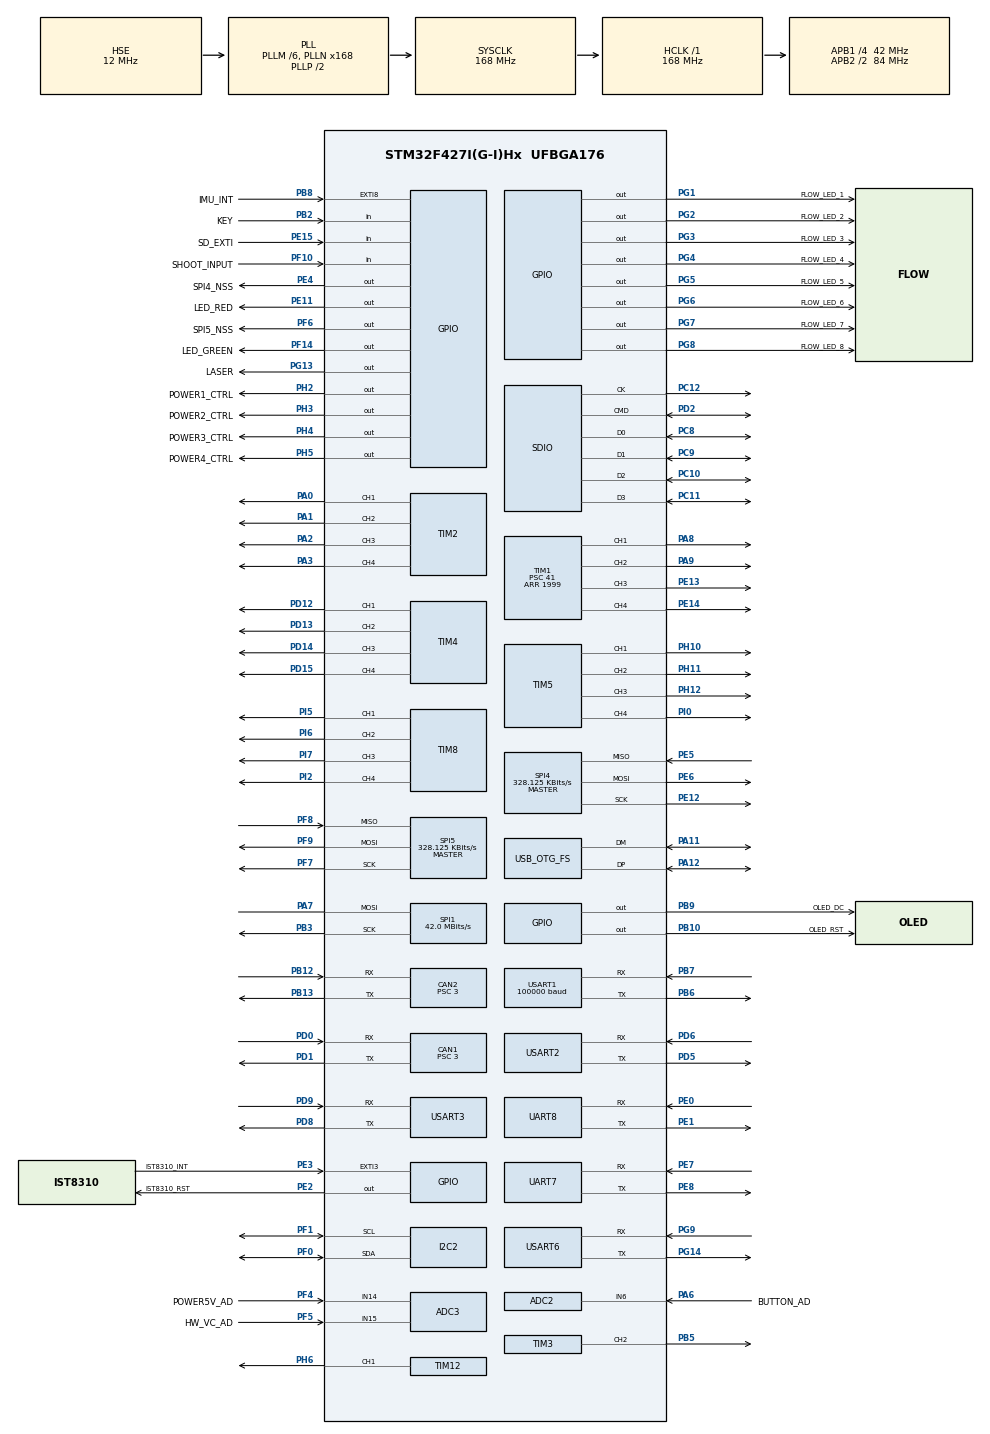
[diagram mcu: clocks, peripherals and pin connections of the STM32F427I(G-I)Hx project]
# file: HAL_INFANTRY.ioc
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ADC1.Channel-1\#ChannelRegularConversion=ADC_CHANNEL_TEMPSENSOR
ADC1.NbrOfConversionFlag=1
ADC1.Rank-1\#ChannelRegularConversion=1
ADC1.SamplingTime-1\#ChannelRegularConversion=ADC_SAMPLETIME_3CYCLES
ADC1.master=1
ADC2.Channel-0\#ChannelRegularConversion=ADC_CHANNEL_6
ADC2.NbrOfConversionFlag=1
ADC2.Rank-0\#ChannelRegularConversion=1
ADC2.SamplingTime-0\#ChannelRegularConversion=ADC_SAMPLETIME_3CYCLES
ADC3.Channel-0\#ChannelRegularConversion=ADC_CHANNEL_14
ADC3.NbrOfConversionFlag=1
ADC3.Rank-0\#ChannelRegularConversion=1
ADC3.SamplingTime-0\#ChannelRegularConversion=ADC_SAMPLETIME_3CYCLES
CAN1.BS1=CAN_BS1_10TQ
CAN1.BS2=CAN_BS2_3TQ
CAN1.CalculateTimeQuantum=71.42857142857143
CAN1.Prescaler=3
CAN2.BS1=CAN_BS1_10TQ
CAN2.BS2=CAN_BS2_3TQ
CAN2.CalculateTimeQuantum=71.42857142857143
CAN2.Prescaler=3
Dma.Request0=USART1_RX
Dma.Request1=USART6_RX
Dma.Request2=USART6_TX
Dma.Request3=SPI5_RX
Dma.Request4=SPI5_TX
Dma.Request5=USART2_RX
Dma.Request6=USART2_TX
Dma.SPI5_RX.3.Direction=DMA_PERIPH_TO_MEMORY
Dma.SPI5_RX.3.FIFOMode=DMA_FIFOMODE_DISABLE
Dma.SPI5_RX.3.Instance=DMA2_Stream5
Dma.SPI5_RX.3.MemDataAlignment=DMA_MDATAALIGN_BYTE
Dma.SPI5_RX.3.MemInc=DMA_MINC_ENABLE
Dma.SPI5_RX.3.Mode=DMA_NORMAL
Dma.SPI5_RX.3.PeriphDataAlignment=DMA_PDATAALIGN_BYTE
Dma.SPI5_RX.3.PeriphInc=DMA_PINC_DISABLE
Dma.SPI5_RX.3.Priority=DMA_PRIORITY_HIGH
Dma.SPI5_TX.4.Direction=DMA_MEMORY_TO_PERIPH
Dma.SPI5_TX.4.FIFOMode=DMA_FIFOMODE_DISABLE
Dma.SPI5_TX.4.Instance=DMA2_Stream4
Dma.SPI5_TX.4.MemDataAlignment=DMA_MDATAALIGN_BYTE
Dma.SPI5_TX.4.MemInc=DMA_MINC_ENABLE
Dma.SPI5_TX.4.Mode=DMA_NORMAL
Dma.SPI5_TX.4.PeriphDataAlignment=DMA_PDATAALIGN_BYTE
Dma.SPI5_TX.4.PeriphInc=DMA_PINC_DISABLE
Dma.SPI5_TX.4.Priority=DMA_PRIORITY_MEDIUM
Dma.USART1_RX.0.Direction=DMA_PERIPH_TO_MEMORY
Dma.USART1_RX.0.FIFOMode=DMA_FIFOMODE_DISABLE
Dma.USART1_RX.0.Instance=DMA2_Stream2
Dma.USART1_RX.0.MemDataAlignment=DMA_MDATAALIGN_BYTE
Dma.USART1_RX.0.MemInc=DMA_MINC_ENABLE
Dma.USART1_RX.0.Mode=DMA_CIRCULAR
Dma.USART1_RX.0.PeriphDataAlignment=DMA_PDATAALIGN_BYTE
Dma.USART1_RX.0.PeriphInc=DMA_PINC_DISABLE
Dma.USART1_RX.0.Priority=DMA_PRIORITY_VERY_HIGH
Dma.USART2_RX.5.Direction=DMA_PERIPH_TO_MEMORY
Dma.USART2_RX.5.FIFOMode=DMA_FIFOMODE_DISABLE
Dma.USART2_RX.5.Instance=DMA1_Stream5
Dma.USART2_RX.5.MemDataAlignment=DMA_MDATAALIGN_BYTE
Dma.USART2_RX.5.MemInc=DMA_MINC_ENABLE
Dma.USART2_RX.5.Mode=DMA_CIRCULAR
Dma.USART2_RX.5.PeriphDataAlignment=DMA_PDATAALIGN_BYTE
Dma.USART2_RX.5.PeriphInc=DMA_PINC_DISABLE
Dma.USART2_RX.5.Priority=DMA_PRIORITY_LOW
Dma.USART2_TX.6.Direction=DMA_MEMORY_TO_PERIPH
Dma.USART2_TX.6.FIFOMode=DMA_FIFOMODE_DISABLE
Dma.USART2_TX.6.Instance=DMA1_Stream6
Dma.USART2_TX.6.MemDataAlignment=DMA_MDATAALIGN_BYTE
Dma.USART2_TX.6.MemInc=DMA_MINC_ENABLE
Dma.USART2_TX.6.Mode=DMA_NORMAL
Dma.USART2_TX.6.PeriphDataAlignment=DMA_PDATAALIGN_BYTE
Dma.USART2_TX.6.PeriphInc=DMA_PINC_DISABLE
Dma.USART2_TX.6.Priority=DMA_PRIORITY_LOW
Dma.USART6_RX.1.Direction=DMA_PERIPH_TO_MEMORY
Dma.USART6_RX.1.FIFOMode=DMA_FIFOMODE_DISABLE
Dma.USART6_RX.1.Instance=DMA2_Stream1
Dma.USART6_RX.1.MemDataAlignment=DMA_MDATAALIGN_BYTE
Dma.USART6_RX.1.MemInc=DMA_MINC_ENABLE
Dma.USART6_RX.1.Mode=DMA_NORMAL
Dma.USART6_RX.1.PeriphDataAlignment=DMA_PDATAALIGN_BYTE
Dma.USART6_RX.1.PeriphInc=DMA_PINC_DISABLE
Dma.USART6_RX.1.Priority=DMA_PRIORITY_LOW
Dma.USART6_TX.2.Direction=DMA_MEMORY_TO_PERIPH
Dma.USART6_TX.2.FIFOMode=DMA_FIFOMODE_DISABLE
Dma.USART6_TX.2.Instance=DMA2_Stream6
Dma.USART6_TX.2.MemDataAlignment=DMA_MDATAALIGN_BYTE
Dma.USART6_TX.2.MemInc=DMA_MINC_ENABLE
Dma.USART6_TX.2.Mode=DMA_NORMAL
Dma.USART6_TX.2.PeriphDataAlignment=DMA_PDATAALIGN_BYTE
Dma.USART6_TX.2.PeriphInc=DMA_PINC_DISABLE
Dma.USART6_TX.2.Priority=DMA_PRIORITY_LOW
FREERTOS.INCLUDE_pcTaskGetTaskName=1
FREERTOS.INCLUDE_uxTaskGetStackHighWaterMark=1
FREERTOS.INCLUDE_xTaskGetHandle=1
FREERTOS.Tasks01=led_trigger,-2,128,led_trigger_task,As weak,NULL,Dynamic,NULL,NULL
I2C2.I2C_Mode=I2C_Fast
Mcu.Family=STM32F4
Mcu.Name=STM32F427I(G-I)Hx
Mcu.Package=UFBGA176
NVIC.CAN1_RX0_IRQn=true\:5\:0\:false\:false\:true\:true\:true\:true
NVIC.CAN2_RX0_IRQn=true\:5\:0\:false\:false\:true\:true\:true\:true
NVIC.DMA1_Stream5_IRQn=true\:5\:0\:true\:false\:false\:true\:false\:false
NVIC.DMA1_Stream6_IRQn=true\:5\:0\:false\:false\:false\:true\:false\:false
NVIC.DMA2_Stream1_IRQn=true\:5\:0\:false\:false\:true\:true\:false\:true
NVIC.DMA2_Stream2_IRQn=true\:5\:0\:false\:false\:false\:true\:false\:false
NVIC.DMA2_Stream4_IRQn=true\:5\:0\:false\:false\:true\:true\:false\:true
NVIC.DMA2_Stream5_IRQn=true\:5\:0\:false\:false\:false\:true\:false\:false
NVIC.DMA2_Stream6_IRQn=true\:5\:0\:false\:false\:true\:true\:false\:true
NVIC.EXTI3_IRQn=true\:5\:0\:false\:false\:true\:true\:true\:true
NVIC.EXTI9_5_IRQn=true\:5\:0\:false\:false\:true\:true\:true\:true
NVIC.OTG_FS_IRQn=true\:5\:0\:false\:false\:true\:true\:true\:true
NVIC.PriorityGroup=NVIC_PRIORITYGROUP_4
NVIC.USART1_IRQn=true\:5\:0\:false\:false\:false\:true\:true\:false
NVIC.USART2_IRQn=true\:5\:0\:false\:false\:false\:true\:true\:false
PA0/WKUP.Signal=S_TIM2_CH1_ETR
PA1.Signal=S_TIM2_CH2
PA11.Mode=Device_Only
PA11.Signal=USB_OTG_FS_DM
PA12.Mode=Device_Only
PA12.Signal=USB_OTG_FS_DP
PA13.Mode=Serial_Wire
PA13.Signal=SYS_JTMS-SWDIO
PA14.Mode=Serial_Wire
PA14.Signal=SYS_JTCK-SWCLK
PA2.Signal=S_TIM2_CH3
PA3.Signal=S_TIM2_CH4
PA6.GPIO_Label=BUTTON_AD
PA6.Signal=ADCx_IN6
PA7.Mode=Simplex_Bidirectional_Master
PA7.Signal=SPI1_MOSI
PA8.Signal=S_TIM1_CH1
PA9.Signal=S_TIM1_CH2
PB10.GPIO_Label=OLED_RST
PB10.GPIO_PuPd=GPIO_PULLUP
PB10.GPIO_Speed=GPIO_SPEED_FREQ_LOW
PB10.PinState=GPIO_PIN_SET
PB10.Signal=GPIO_Output
PB12.Mode=Slave
PB12.Signal=CAN2_RX
PB13.Mode=Slave
PB13.Signal=CAN2_TX
PB2/BOOT1.GPIO_Label=KEY
PB2/BOOT1.Signal=GPIO_Input
PB3.Mode=Simplex_Bidirectional_Master
PB3.Signal=SPI1_SCK
PB5.Signal=S_TIM3_CH2
PB6.Mode=Asynchronous
PB6.Signal=USART1_TX
PB7.Mode=Asynchronous
PB7.Signal=USART1_RX
PB8.GPIO_Label=IMU_INT
PB8.GPIO_ModeDefaultEXTI=GPIO_MODE_IT_FALLING
PB8.GPIO_PuPd=GPIO_PULLUP
PB8.Signal=GPXTI8
PB9.GPIO_Label=OLED_DC
PB9.GPIO_PuPd=GPIO_PULLUP
PB9.GPIO_Speed=GPIO_SPEED_FREQ_VERY_HIGH
PB9.PinState=GPIO_PIN_SET
PB9.Signal=GPIO_Output
PC10.Mode=SD_4_bits_Wide_bus
PC10.Signal=SDIO_D2
PC11.Mode=SD_4_bits_Wide_bus
PC11.Signal=SDIO_D3
PC12.Mode=SD_4_bits_Wide_bus
PC12.Signal=SDIO_CK
PC8.Mode=SD_4_bits_Wide_bus
PC8.Signal=SDIO_D0
PC9.Mode=SD_4_bits_Wide_bus
PC9.Signal=SDIO_D1
PD0.Mode=Master
PD0.Signal=CAN1_RX
PD1.Mode=Master
PD1.Signal=CAN1_TX
PD12.Signal=S_TIM4_CH1
PD13.Signal=S_TIM4_CH2
PD14.Signal=S_TIM4_CH3
PD15.Signal=S_TIM4_CH4
PD2.Mode=SD_4_bits_Wide_bus
PD2.Signal=SDIO_CMD
PD5.Mode=Asynchronous
PD5.Signal=USART2_TX
PD6.Mode=Asynchronous
PD6.Signal=USART2_RX
PD8.Mode=Asynchronous
PD8.Signal=USART3_TX
PD9.Mode=Asynchronous
PD9.Signal=USART3_RX
PE0.Mode=Asynchronous
PE0.Signal=UART8_RX
PE1.Mode=Asynchronous
PE1.Signal=UART8_TX
PE11.GPIO_Label=LED_RED
PE11.GPIO_ModeDefaultOutputPP=GPIO_MODE_OUTPUT_PP
PE11.GPIO_PuPd=GPIO_PULLUP
PE11.GPIO_Speed=GPIO_SPEED_FREQ_MEDIUM
PE11.PinState=GPIO_PIN_SET
PE11.Signal=GPIO_Output
PE12.Mode=Full_Duplex_Master
PE12.Signal=SPI4_SCK
PE13.Signal=S_TIM1_CH3
PE14.Signal=S_TIM1_CH4
PE15.GPIO_Label=SD_EXTI
PE15.GPIO_PuPd=GPIO_PULLUP
PE15.Signal=GPIO_Input
PE2.GPIO_Label=IST8310_RST
PE2.GPIO_PuPd=GPIO_PULLUP
PE2.GPIO_Speed=GPIO_SPEED_FREQ_LOW
PE2.PinState=GPIO_PIN_SET
PE2.Signal=GPIO_Output
PE3.GPIO_Label=IST8310_INT
PE3.GPIO_ModeDefaultEXTI=GPIO_MODE_IT_FALLING
PE3.GPIO_PuPd=GPIO_PULLUP
PE3.Signal=GPXTI3
PE4.GPIO_Label=SPI4_NSS
PE4.GPIO_PuPd=GPIO_PULLUP
PE4.GPIO_Speed=GPIO_SPEED_FREQ_VERY_HIGH
PE4.PinState=GPIO_PIN_SET
PE4.Signal=GPIO_Output
PE5.Mode=Full_Duplex_Master
PE5.Signal=SPI4_MISO
PE6.Mode=Full_Duplex_Master
PE6.Signal=SPI4_MOSI
PE7.Mode=Asynchronous
PE7.Signal=UART7_RX
PE8.Mode=Asynchronous
PE8.Signal=UART7_TX
PF0.Mode=I2C
PF0.Signal=I2C2_SDA
PF1.Mode=I2C
PF1.Signal=I2C2_SCL
PF10.GPIO_Label=SHOOT_INPUT
PF10.GPIO_PuPd=GPIO_PULLUP
PF10.Signal=GPIO_Input
PF14.GPIO_Label=LED_GREEN
PF14.GPIO_PuPd=GPIO_PULLUP
PF14.GPIO_Speed=GPIO_SPEED_FREQ_MEDIUM
PF14.PinState=GPIO_PIN_SET
PF14.Signal=GPIO_Output
PF4.GPIO_Label=POWER5V_AD
PF4.Mode=IN14
PF4.Signal=ADC3_IN14
PF5.GPIO_Label=HW_VC_AD
PF5.Mode=IN15
PF5.Signal=ADC3_IN15
PF6.GPIO_Label=SPI5_NSS
PF6.GPIO_PuPd=GPIO_PULLUP
PF6.GPIO_Speed=GPIO_SPEED_FREQ_VERY_HIGH
PF6.PinState=GPIO_PIN_SET
PF6.Signal=GPIO_Output
PF7.Mode=Full_Duplex_Master
PF7.Signal=SPI5_SCK
PF8.Mode=Full_Duplex_Master
PF8.Signal=SPI5_MISO
PF9.Mode=Full_Duplex_Master
PF9.Signal=SPI5_MOSI
PG1.GPIO_Label=FLOW_LED_1
PG1.GPIO_PuPd=GPIO_PULLUP
PG1.GPIO_Speed=GPIO_SPEED_FREQ_MEDIUM
PG1.PinState=GPIO_PIN_SET
PG1.Signal=GPIO_Output
PG13.GPIO_Label=LASER
PG13.GPIO_ModeDefaultOutputPP=GPIO_MODE_OUTPUT_PP
PG13.GPIO_PuPd=GPIO_PULLUP
PG13.GPIO_Speed=GPIO_SPEED_FREQ_MEDIUM
PG13.PinState=GPIO_PIN_SET
PG13.Signal=GPIO_Output
PG14.Mode=Asynchronous
PG14.Signal=USART6_TX
PG2.GPIO_Label=FLOW_LED_2
PG2.GPIO_PuPd=GPIO_PULLUP
PG2.GPIO_Speed=GPIO_SPEED_FREQ_MEDIUM
PG2.PinState=GPIO_PIN_SET
PG2.Signal=GPIO_Output
PG3.GPIO_Label=FLOW_LED_3
PG3.GPIO_PuPd=GPIO_PULLUP
PG3.GPIO_Speed=GPIO_SPEED_FREQ_MEDIUM
PG3.PinState=GPIO_PIN_SET
PG3.Signal=GPIO_Output
PG4.GPIO_Label=FLOW_LED_4
PG4.GPIO_PuPd=GPIO_PULLUP
PG4.GPIO_Speed=GPIO_SPEED_FREQ_MEDIUM
PG4.PinState=GPIO_PIN_SET
PG4.Signal=GPIO_Output
PG5.GPIO_Label=FLOW_LED_5
PG5.GPIO_PuPd=GPIO_PULLUP
PG5.GPIO_Speed=GPIO_SPEED_FREQ_MEDIUM
PG5.PinState=GPIO_PIN_SET
PG5.Signal=GPIO_Output
PG6.GPIO_Label=FLOW_LED_6
PG6.GPIO_PuPd=GPIO_PULLUP
PG6.GPIO_Speed=GPIO_SPEED_FREQ_MEDIUM
PG6.PinState=GPIO_PIN_SET
PG6.Signal=GPIO_Output
PG7.GPIO_Label=FLOW_LED_7
PG7.GPIO_PuPd=GPIO_PULLUP
PG7.GPIO_Speed=GPIO_SPEED_FREQ_MEDIUM
PG7.PinState=GPIO_PIN_SET
PG7.Signal=GPIO_Output
PG8.GPIO_Label=FLOW_LED_8
PG8.GPIO_PuPd=GPIO_PULLUP
PG8.GPIO_Speed=GPIO_SPEED_FREQ_MEDIUM
PG8.PinState=GPIO_PIN_SET
PG8.Signal=GPIO_Output
PG9.Mode=Asynchronous
PG9.Signal=USART6_RX
PH0/OSC_IN.Mode=HSE-External-Oscillator
PH0/OSC_IN.Signal=RCC_OSC_IN
PH1/OSC_OUT.Mode=HSE-External-Oscillator
PH1/OSC_OUT.Signal=RCC_OSC_OUT
PH10.Signal=S_TIM5_CH1
PH11.Signal=S_TIM5_CH2
PH12.Signal=S_TIM5_CH3
PH2.GPIO_Label=POWER1_CTRL
PH2.GPIO_ModeDefaultOutputPP=GPIO_MODE_OUTPUT_PP
PH2.GPIO_PuPd=GPIO_PULLDOWN
PH2.GPIO_Speed=GPIO_SPEED_FREQ_MEDIUM
PH2.PinState=GPIO_PIN_RESET
PH2.Signal=GPIO_Output
PH3.GPIO_Label=POWER2_CTRL
PH3.GPIO_PuPd=GPIO_PULLDOWN
PH3.GPIO_Speed=GPIO_SPEED_FREQ_MEDIUM
PH3.PinState=GPIO_PIN_RESET
PH3.Signal=GPIO_Output
PH4.GPIO_Label=POWER3_CTRL
PH4.GPIO_PuPd=GPIO_PULLDOWN
PH4.GPIO_Speed=GPIO_SPEED_FREQ_MEDIUM
PH4.Signal=GPIO_Output
PH5.GPIO_Label=POWER4_CTRL
PH5.GPIO_PuPd=GPIO_PULLDOWN
PH5.GPIO_Speed=GPIO_SPEED_FREQ_MEDIUM
PH5.Signal=GPIO_Output
PH6.Signal=S_TIM12_CH1
PI0.Signal=S_TIM5_CH4
PI2.Signal=S_TIM8_CH4
PI5.Signal=S_TIM8_CH1
PI6.Signal=S_TIM8_CH2
PI7.Signal=S_TIM8_CH3
ProjectManager.HeapSize=0x2000
ProjectManager.StackSize=0x0
ProjectManager.TargetToolchain=MDK-ARM V5
RCC.48MHZClocksFreq_Value=48000000
RCC.AHBFreq_Value=168000000
RCC.APB1CLKDivider=RCC_HCLK_DIV4
RCC.APB1Freq_Value=42000000
RCC.APB1TimFreq_Value=84000000
RCC.APB2CLKDivider=RCC_HCLK_DIV2
RCC.APB2Freq_Value=84000000
RCC.APB2TimFreq_Value=168000000
RCC.CortexFreq_Value=168000000
RCC.HCLKFreq_Value=168000000
RCC.HSE_VALUE=12000000
RCC.HSI_VALUE=16000000
RCC.LSE_VALUE=32768
RCC.PLLM=6
RCC.PLLN=168
RCC.PLLQ=7
RCC.RCC_RTC_Clock_SourceVirtual=RCC_RTCCLKSOURCE_HSE_DIV30
RCC.RCC_RTC_Clock_Source_FROM_HSE=RCC_RTCCLKSOURCE_HSE_DIV30
RCC.SYSCLKFreq_VALUE=168000000
RCC.SYSCLKSource=RCC_SYSCLKSOURCE_PLLCLK
RCC.VCOOutputFreq_Value=336000000
RTC.AsynchPrediv=124
RTC.SynchPrediv=3199
SH.ADCx_IN6.0=ADC2_IN6,IN6
SH.S_TIM12_CH1.0=TIM12_CH1,PWM Generation1 CH1
SH.S_TIM1_CH1.0=TIM1_CH1,PWM Generation1 CH1
SH.S_TIM1_CH2.0=TIM1_CH2,PWM Generation2 CH2
SH.S_TIM1_CH3.0=TIM1_CH3,PWM Generation3 CH3
SH.S_TIM1_CH4.0=TIM1_CH4,PWM Generation4 CH4
SH.S_TIM2_CH1_ETR.0=TIM2_CH1,PWM Generation1 CH1
SH.S_TIM2_CH2.0=TIM2_CH2,PWM Generation2 CH2
SH.S_TIM2_CH3.0=TIM2_CH3,PWM Generation3 CH3
SH.S_TIM2_CH4.0=TIM2_CH4,PWM Generation4 CH4
SH.S_TIM3_CH2.0=TIM3_CH2,PWM Generation2 CH2
SH.S_TIM4_CH1.0=TIM4_CH1,PWM Generation1 CH1
SH.S_TIM4_CH2.0=TIM4_CH2,PWM Generation2 CH2
SH.S_TIM4_CH3.0=TIM4_CH3,PWM Generation3 CH3
SH.S_TIM4_CH4.0=TIM4_CH4,PWM Generation4 CH4
SH.S_TIM5_CH1.0=TIM5_CH1,PWM Generation1 CH1
SH.S_TIM5_CH2.0=TIM5_CH2,PWM Generation2 CH2
SH.S_TIM5_CH3.0=TIM5_CH3,PWM Generation3 CH3
SH.S_TIM5_CH4.0=TIM5_CH4,PWM Generation4 CH4
SH.S_TIM8_CH1.0=TIM8_CH1,PWM Generation1 CH1
SH.S_TIM8_CH2.0=TIM8_CH2,PWM Generation2 CH2
SH.S_TIM8_CH3.0=TIM8_CH3,PWM Generation3 CH3
SH.S_TIM8_CH4.0=TIM8_CH4,PWM Generation4 CH4
SPI1.CalculateBaudRate=42.0 MBits/s
SPI1.Direction=SPI_DIRECTION_1LINE
SPI1.Mode=SPI_MODE_MASTER
SPI1.VirtualType=VM_MASTER
SPI4.BaudRatePrescaler=SPI_BAUDRATEPRESCALER_256
SPI4.CLKPhase=SPI_PHASE_2EDGE
SPI4.CLKPolarity=SPI_POLARITY_HIGH
SPI4.CalculateBaudRate=328.125 KBits/s
SPI4.Direction=SPI_DIRECTION_2LINES
SPI4.Mode=SPI_MODE_MASTER
SPI4.VirtualType=VM_MASTER
SPI5.BaudRatePrescaler=SPI_BAUDRATEPRESCALER_256
SPI5.CLKPhase=SPI_PHASE_2EDGE
SPI5.CLKPolarity=SPI_POLARITY_HIGH
SPI5.CalculateBaudRate=328.125 KBits/s
SPI5.Direction=SPI_DIRECTION_2LINES
SPI5.Mode=SPI_MODE_MASTER
SPI5.VirtualType=VM_MASTER
TIM1.Channel-PWM\ Generation1\ CH1=TIM_CHANNEL_1
TIM1.Channel-PWM\ Generation2\ CH2=TIM_CHANNEL_2
TIM1.Channel-PWM\ Generation3\ CH3=TIM_CHANNEL_3
TIM1.Channel-PWM\ Generation4\ CH4=TIM_CHANNEL_4
TIM1.ClockDivision=TIM_CLOCKDIVISION_DIV4
TIM1.Period=1999
TIM1.Prescaler=41
TIM1.Pulse-PWM\ Generation1\ CH1=1000
TIM1.Pulse-PWM\ Generation2\ CH2=1000
TIM1.Pulse-PWM\ Generation3\ CH3=1000
TIM1.Pulse-PWM\ Generation4\ CH4=1000
TIM12.Channel-PWM\ Generation1\ CH1=TIM_CHANNEL_1
TIM12.ClockDivision=TIM_CLOCKDIVISION_DIV4
TIM12.Period=30000
TIM12.Prescaler=90
TIM12.Pulse-PWM\ Generation1\ CH1=0
TIM2.Channel-PWM\ Generation1\ CH1=TIM_CHANNEL_1
TIM2.Channel-PWM\ Generation2\ CH2=TIM_CHANNEL_2
TIM2.Channel-PWM\ Generation3\ CH3=TIM_CHANNEL_3
TIM2.Channel-PWM\ Generation4\ CH4=TIM_CHANNEL_4
TIM3.Channel-PWM\ Generation2\ CH2=TIM_CHANNEL_2
TIM3.Period=5000
TIM4.Channel-PWM\ Generation1\ CH1=TIM_CHANNEL_1
TIM4.Channel-PWM\ Generation2\ CH2=TIM_CHANNEL_2
TIM4.Channel-PWM\ Generation3\ CH3=TIM_CHANNEL_3
TIM4.Channel-PWM\ Generation4\ CH4=TIM_CHANNEL_4
TIM5.Channel-PWM\ Generation1\ CH1=TIM_CHANNEL_1
TIM5.Channel-PWM\ Generation2\ CH2=TIM_CHANNEL_2
TIM5.Channel-PWM\ Generation3\ CH3=TIM_CHANNEL_3
TIM5.Channel-PWM\ Generation4\ CH4=TIM_CHANNEL_4
TIM8.Channel-PWM\ Generation1\ CH1=TIM_CHANNEL_1
TIM8.Channel-PWM\ Generation2\ CH2=TIM_CHANNEL_2
TIM8.Channel-PWM\ Generation3\ CH3=TIM_CHANNEL_3
TIM8.Channel-PWM\ Generation4\ CH4=TIM_CHANNEL_4
UART7.VirtualMode=Asynchronous
UART8.VirtualMode=Asynchronous
USART1.BaudRate=100000
USART1.Mode=MODE_RX
USART1.Parity=PARITY_EVEN
USART1.VirtualMode=VM_ASYNC
USART2.VirtualMode=VM_ASYNC
USART3.VirtualMode=VM_ASYNC
USART6.VirtualMode=VM_ASYNC
USB_DEVICE.CLASS_NAME_FS=CDC
USB_DEVICE.VirtualMode-CDC_FS=Cdc
USB_DEVICE.VirtualModeFS=Cdc_FS
USB_OTG_FS.VirtualMode=Device_Only
VP_ADC1_TempSens_Input.Mode=IN-TempSens
VP_CRC_VS_CRC.Mode=CRC_Activate
VP_FREERTOS_VS_CMSIS_V1.Mode=CMSIS_V1
VP_RNG_VS_RNG.Mode=RNG_Activate
VP_RTC_VS_RTC_Activate.Mode=RTC_Enabled
VP_RTC_VS_RTC_Calendar.Mode=RTC_Calendar
VP_TIM12_VS_ClockSourceINT.Mode=Internal
VP_TIM1_VS_ClockSourceINT.Mode=Internal
VP_TIM2_VS_ClockSourceINT.Mode=Internal
VP_TIM3_VS_ClockSourceINT.Mode=Internal
VP_TIM4_VS_ClockSourceINT.Mode=Internal
VP_TIM5_VS_ClockSourceINT.Mode=Internal
VP_TIM8_VS_ClockSourceINT.Mode=Internal
VP_USB_DEVICE_VS_USB_DEVICE_CDC_FS.Mode=CDC_FS
board=custom

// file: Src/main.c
/* USER CODE BEGIN Header */
/**
  ******************************************************************************
  * @file           : main.c
  * @brief          : Main program body
  ******************************************************************************
  * @attention
  *
  * <h2><center>&copy; Copyright (c) 2019 STMicroelectronics.
  * All rights reserved.</center></h2>
  *
  * This software component is licensed by ST under Ultimate Liberty license
  * SLA0044, the "License"; You may not use this file except in compliance with
  * the License. You may obtain a copy of the License at:
  *                             www.st.com/SLA0044
  *
  ******************************************************************************
  */
/* USER CODE END Header */

#include "main.h"
#include "cmsis_os.h"
#include "usb_device.h"
#include "A_STAR.h"

/* Private includes ---------3-------------------------------------------------*/
/* USER CODE BEGIN Includes */
#include "calibrate_task.h"
#include "Detect_Task.h"
#include "Gimbal_Task.h"
#include "INS_task.h"
#include "bsp_power_ctrl.h"
#include "chassis_task.h"
#include "referee.h"
#include "protocol.h"
#include "pwm.h"
#include "up_control_task.h"
/* USER CODE END Includes */

ADC_HandleTypeDef hadc1;
ADC_HandleTypeDef hadc2;
ADC_HandleTypeDef hadc3;

CAN_HandleTypeDef hcan1;
CAN_HandleTypeDef hcan2;

CRC_HandleTypeDef hcrc;

I2C_HandleTypeDef hi2c2;

RNG_HandleTypeDef hrng;

RTC_HandleTypeDef hrtc;

SD_HandleTypeDef hsd;

SPI_HandleTypeDef hspi1;
SPI_HandleTypeDef hspi4;
SPI_HandleTypeDef hspi5;
DMA_HandleTypeDef hdma_spi5_rx;
DMA_HandleTypeDef hdma_spi5_tx;

TIM_HandleTypeDef htim1;
TIM_HandleTypeDef htim2;
TIM_HandleTypeDef htim3;
TIM_HandleTypeDef htim4;
TIM_HandleTypeDef htim5;
TIM_HandleTypeDef htim8;
TIM_HandleTypeDef htim12;

UART_HandleTypeDef huart7;
UART_HandleTypeDef huart8;
UART_HandleTypeDef huart1;
UART_HandleTypeDef huart2;
UART_HandleTypeDef huart3;
UART_HandleTypeDef huart6;
DMA_HandleTypeDef hdma_usart1_rx;
DMA_HandleTypeDef hdma_usart2_rx;
DMA_HandleTypeDef hdma_usart2_tx;
DMA_HandleTypeDef hdma_usart6_rx;
DMA_HandleTypeDef hdma_usart6_tx;

extern QueueHandle_t auto_queue;
extern QueueHandle_t referee_send_queue;
extern TimerHandle_t referee_send_handle;

osThreadId led_triggerHandle;
/* USER CODE BEGIN PV */
osThreadId cali_taskHandle;
osThreadId detect_taskHandle;
osThreadId ins_taskHandle;
osThreadId chassis_taskHandle;
osThreadId chassis_distance_taskHandle;
osThreadId referee_taskHandle;
osThreadId chassis_distance_send_taskHandle;
TaskHandle_t up_control_taskHandle;
extern void set_pwm( void);
/* USER CODE END PV */

void SystemClock_Config(void);
static void MX_GPIO_Init(void);
static void MX_DMA_Init(void);
static void MX_ADC1_Init(void);
static void MX_ADC3_Init(void);
static void MX_CAN1_Init(void);
static void MX_CAN2_Init(void);
static void MX_RTC_Init(void);
static void MX_SDIO_SD_Init(void);
static void MX_SPI1_Init(void);
static void MX_SPI5_Init(void);
static void MX_TIM2_Init(void);
static void MX_TIM3_Init(void);
static void MX_TIM4_Init(void);
static void MX_TIM5_Init(void);
static void MX_TIM8_Init(void);
static void MX_TIM12_Init(void);
static void MX_UART7_Init(void);
static void MX_UART8_Init(void);
static void MX_USART1_UART_Init(void);
static void MX_USART2_UART_Init(void);
static void MX_USART3_UART_Init(void);
static void MX_USART6_UART_Init(void);
static void MX_CRC_Init(void);
static void MX_I2C2_Init(void);
static void MX_RNG_Init(void);
static void MX_SPI4_Init(void);
static void MX_TIM1_Init(void);
static void MX_ADC2_Init(void);
void led_trigger_task(void const * argument);

/* USER CODE BEGIN PFP */
extern void remote_control_init(void);
extern void chassis_distance_calc_task(void const * argument);
extern void chassis_distance_send_task(void const * argument);
extern void referee_task(void const * argument);
extern void referee_send_task(void const * argument);
extern void up_task(void const *pvParameters);

/* USER CODE END PFP */

SemaphoreHandle_t apriltag_handle;

float ggg ;
float poi;
float zxc;

int main(void)
{
	//A_Star();
  /* USER CODE BEGIN 1 */

  /* MCU Configuration--------------------------------------------------------*/

  /* Reset of all peripherals, Initializes the Flash interface and the Systick. */
  HAL_Init();

  /* USER CODE BEGIN Init */

  /* USER CODE END Init */

  /* Configure the system clock */
  SystemClock_Config();

  /* USER CODE BEGIN SysInit */

  /* USER CODE END SysInit */

  /* Initialize all configured peripherals */
  MX_GPIO_Init();
  MX_DMA_Init();
  MX_ADC1_Init();
  MX_ADC3_Init();
  MX_CAN1_Init();
  MX_CAN2_Init();
  MX_RTC_Init();
  MX_SDIO_SD_Init();
  MX_SPI1_Init();
  MX_SPI5_Init();
  MX_TIM2_Init();
  MX_TIM3_Init();
  MX_TIM4_Init();
  MX_TIM5_Init();
  MX_TIM8_Init();
  MX_TIM12_Init();
  MX_UART7_Init();
  MX_UART8_Init();
  MX_USART1_UART_Init();
  MX_USART2_UART_Init();
  MX_USART3_UART_Init();
  MX_USART6_UART_Init();
  MX_CRC_Init();
  MX_I2C2_Init();
  MX_RNG_Init();
  MX_SPI4_Init();
  MX_TIM1_Init();
  MX_ADC2_Init();
  /* USER CODE BEGIN 2 */
    remote_control_init();
    cali_param_init();

    power_ctrl_on(0);
    HAL_Delay(137);
    power_ctrl_on(1);
    HAL_Delay(137);
    power_ctrl_on(2);
    HAL_Delay(137);
    power_ctrl_on(3);
    HAL_Delay(137);

//	steering_engine asd;
//		steering_engine qwe;
//	  steering_engine mnb;
//		asd.port = B;
//		qwe.port = A;
//		mnb.port = C;
//		pwm_all_init();
//		while(1){
//		change_pwm(&asd, ggg);
//			change_pwm(&qwe, poi);
//			change_pwm(&mnb,zxc);
//		}
  /* USER CODE END 1 */

  /* USER CODE END 2 */

  apriltag_handle=xSemaphoreCreateMutex();

//  steering_engine pwminit;
//	pwminit.htim=htim4;
//	pwminit.channel=TIM_CHANNEL_1;
//  while(1){
//
//
//	  change_pwm(&pwminit,0.0);
//	  osDelay(1000);
//	  change_pwm(&pwminit,90.0);
//	  osDelay(1000);
//}

	referee_send_queue = xQueueCreate(RECIVE_BUFFER_SIZE, RECIVE_TERM_SIZE);
	auto_queue = xQueueCreate(AUTO_RECIVE_BUFFER_SIZE, sizeof(auto_pack_t));

	xTaskCreate((TaskFunction_t)referee_send_task, "send_task", 256, NULL, osPriorityHigh, &referee_send_handle);

	xTaskCreate((TaskFunction_t)up_task, "send_task", 256, NULL, osPriorityHigh, &up_control_taskHandle);

  /* Create the thread(s) */
  /* definition and creation of led_trigger */
  osThreadDef(led_trigger, led_trigger_task, osPriorityLow, 0, 128);
  led_triggerHandle = osThreadCreate(osThread(led_trigger), NULL);

  /* USER CODE BEGIN RTOS_THREADS */
  /* add threads, ... */
  osThreadDef(ins_task, INSTask, osPriorityHigh, 0, 512);
  ins_taskHandle = osThreadCreate(osThread(ins_task), NULL);

//  osThreadDef(cali_task, calibrate_task, osPriorityNormal, 0, 512);
//  cali_taskHandle = osThreadCreate(osThread(cali_task), NULL);

  osThreadDef(detect, DetectTask, osPriorityNormal, 0, 256);
  detect_taskHandle = osThreadCreate(osThread(detect), NULL);

  osThreadDef(chassis, chassis_task, osPriorityHigh, 0, 512);
  chassis_taskHandle = osThreadCreate(osThread(chassis), NULL);

  osThreadDef(chassis_send, chassis_distance_send_task, osPriorityHigh, 0, 256);
  chassis_distance_send_taskHandle = osThreadCreate(osThread(chassis_send), NULL);

	osThreadDef(referee, referee_task, osPriorityHigh, 0, 256);
  referee_taskHandle = osThreadCreate(osThread(referee), NULL);

	osThreadDef(chassis_distance, chassis_distance_calc_task, osPriorityRealtime, 0, 256);
  chassis_distance_taskHandle = osThreadCreate(osThread(chassis_distance), NULL);

  /* USER CODE END RTOS_THREADS */

  /* Start scheduler */
  osKernelStart();

  /* We should never get here as control is now taken by the scheduler */

  /* Infinite loop */
  while (1)
  {

  }
}

void SystemClock_Config(void)
{
  RCC_OscInitTypeDef RCC_OscInitStruct = {0};
  RCC_ClkInitTypeDef RCC_ClkInitStruct = {0};
  RCC_PeriphCLKInitTypeDef PeriphClkInitStruct = {0};

  /** Configure the main internal regulator output voltage
  */
  __HAL_RCC_PWR_CLK_ENABLE();
  __HAL_PWR_VOLTAGESCALING_CONFIG(PWR_REGULATOR_VOLTAGE_SCALE1);
  /** Initializes the CPU, AHB and APB busses clocks
  */
  RCC_OscInitStruct.OscillatorType = RCC_OSCILLATORTYPE_HSE;
  RCC_OscInitStruct.HSEState = RCC_HSE_ON;
  RCC_OscInitStruct.PLL.PLLState = RCC_PLL_ON;
  RCC_OscInitStruct.PLL.PLLSource = RCC_PLLSOURCE_HSE;
  RCC_OscInitStruct.PLL.PLLM = 6;
  RCC_OscInitStruct.PLL.PLLN = 168;
  RCC_OscInitStruct.PLL.PLLP = RCC_PLLP_DIV2;
  RCC_OscInitStruct.PLL.PLLQ = 7;
  if (HAL_RCC_OscConfig(&RCC_OscInitStruct) != HAL_OK)
  {
    Error_Handler();
  }
  /** Initializes the CPU, AHB and APB busses clocks
  */
  RCC_ClkInitStruct.ClockType = RCC_CLOCKTYPE_HCLK|RCC_CLOCKTYPE_SYSCLK
                              |RCC_CLOCKTYPE_PCLK1|RCC_CLOCKTYPE_PCLK2;
  RCC_ClkInitStruct.SYSCLKSource = RCC_SYSCLKSOURCE_PLLCLK;
  RCC_ClkInitStruct.AHBCLKDivider = RCC_SYSCLK_DIV1;
  RCC_ClkInitStruct.APB1CLKDivider = RCC_HCLK_DIV4;
  RCC_ClkInitStruct.APB2CLKDivider = RCC_HCLK_DIV2;

  if (HAL_RCC_ClockConfig(&RCC_ClkInitStruct, FLASH_LATENCY_5) != HAL_OK)
  {
    Error_Handler();
  }
  PeriphClkInitStruct.PeriphClockSelection = RCC_PERIPHCLK_RTC;
  PeriphClkInitStruct.RTCClockSelection = RCC_RTCCLKSOURCE_HSE_DIV30;
  if (HAL_RCCEx_PeriphCLKConfig(&PeriphClkInitStruct) != HAL_OK)
  {
    Error_Handler();
  }
}

static void MX_ADC1_Init(void)
{

  ADC_ChannelConfTypeDef sConfig = {0};

  /** Configure the global features of the ADC (Clock, Resolution, Data Alignment and number of conversion)
  */
  hadc1.Instance = ADC1;
  hadc1.Init.ClockPrescaler = ADC_CLOCK_SYNC_PCLK_DIV4;
  hadc1.Init.Resolution = ADC_RESOLUTION_12B;
  hadc1.Init.ScanConvMode = DISABLE;
  hadc1.Init.ContinuousConvMode = DISABLE;
  hadc1.Init.DiscontinuousConvMode = DISABLE;
  hadc1.Init.ExternalTrigConvEdge = ADC_EXTERNALTRIGCONVEDGE_NONE;
  hadc1.Init.ExternalTrigConv = ADC_SOFTWARE_START;
  hadc1.Init.DataAlign = ADC_DATAALIGN_RIGHT;
  hadc1.Init.NbrOfConversion = 1;
  hadc1.Init.DMAContinuousRequests = DISABLE;
  hadc1.Init.EOCSelection = ADC_EOC_SINGLE_CONV;
  if (HAL_ADC_Init(&hadc1) != HAL_OK)
  {
    Error_Handler();
  }
  /** Configure for the selected ADC regular channel its corresponding rank in the sequencer and its sample time.
  */
  sConfig.Channel = ADC_CHANNEL_TEMPSENSOR;
  sConfig.Rank = 1;
  sConfig.SamplingTime = ADC_SAMPLETIME_3CYCLES;
  if (HAL_ADC_ConfigChannel(&hadc1, &sConfig) != HAL_OK)
  {
    Error_Handler();
  }

}

static void MX_ADC2_Init(void)
{

  ADC_ChannelConfTypeDef sConfig = {0};

  /** Configure the global features of the ADC (Clock, Resolution, Data Alignment and number of conversion)
  */
  hadc2.Instance = ADC2;
  hadc2.Init.ClockPrescaler = ADC_CLOCK_SYNC_PCLK_DIV4;
  hadc2.Init.Resolution = ADC_RESOLUTION_12B;
  hadc2.Init.ScanConvMode = DISABLE;
  hadc2.Init.ContinuousConvMode = DISABLE;
  hadc2.Init.DiscontinuousConvMode = DISABLE;
  hadc2.Init.ExternalTrigConvEdge = ADC_EXTERNALTRIGCONVEDGE_NONE;
  hadc2.Init.ExternalTrigConv = ADC_SOFTWARE_START;
  hadc2.Init.DataAlign = ADC_DATAALIGN_RIGHT;
  hadc2.Init.NbrOfConversion = 1;
  hadc2.Init.DMAContinuousRequests = DISABLE;
  hadc2.Init.EOCSelection = ADC_EOC_SINGLE_CONV;
  if (HAL_ADC_Init(&hadc2) != HAL_OK)
  {
    Error_Handler();
  }
  /** Configure for the selected ADC regular channel its corresponding rank in the sequencer and its sample time.
  */
  sConfig.Channel = ADC_CHANNEL_6;
  sConfig.Rank = 1;
  sConfig.SamplingTime = ADC_SAMPLETIME_3CYCLES;
  if (HAL_ADC_ConfigChannel(&hadc2, &sConfig) != HAL_OK)
  {
    Error_Handler();
  }

}

static void MX_ADC3_Init(void)
{

  ADC_ChannelConfTypeDef sConfig = {0};

  /** Configure the global features of the ADC (Clock, Resolution, Data Alignment and number of conversion)
  */
  hadc3.Instance = ADC3;
  hadc3.Init.ClockPrescaler = ADC_CLOCK_SYNC_PCLK_DIV4;
  hadc3.Init.Resolution = ADC_RESOLUTION_12B;
  hadc3.Init.ScanConvMode = DISABLE;
  hadc3.Init.ContinuousConvMode = DISABLE;
  hadc3.Init.DiscontinuousConvMode = DISABLE;
  hadc3.Init.ExternalTrigConvEdge = ADC_EXTERNALTRIGCONVEDGE_NONE;
  hadc3.Init.ExternalTrigConv = ADC_SOFTWARE_START;
  hadc3.Init.DataAlign = ADC_DATAALIGN_RIGHT;
  hadc3.Init.NbrOfConversion = 1;
  hadc3.Init.DMAContinuousRequests = DISABLE;
  hadc3.Init.EOCSelection = ADC_EOC_SINGLE_CONV;
  if (HAL_ADC_Init(&hadc3) != HAL_OK)
  {
    Error_Handler();
  }
  /** Configure for the selected ADC regular channel its corresponding rank in the sequencer and its sample time.
  */
  sConfig.Channel = ADC_CHANNEL_14;
  sConfig.Rank = 1;
  sConfig.SamplingTime = ADC_SAMPLETIME_3CYCLES;
  if (HAL_ADC_ConfigChannel(&hadc3, &sConfig) != HAL_OK)
  {
    Error_Handler();
  }

}

static void MX_CAN1_Init(void)
{

  hcan1.Instance = CAN1;
  hcan1.Init.Prescaler = 3;
  hcan1.Init.Mode = CAN_MODE_NORMAL;
  hcan1.Init.SyncJumpWidth = CAN_SJW_1TQ;
  hcan1.Init.TimeSeg1 = CAN_BS1_10TQ;
  hcan1.Init.TimeSeg2 = CAN_BS2_3TQ;
  hcan1.Init.TimeTriggeredMode = DISABLE;
  hcan1.Init.AutoBusOff = DISABLE;
  hcan1.Init.AutoWakeUp = DISABLE;
  hcan1.Init.AutoRetransmission = DISABLE;
  hcan1.Init.ReceiveFifoLocked = DISABLE;
  hcan1.Init.TransmitFifoPriority = DISABLE;
  if (HAL_CAN_Init(&hcan1) != HAL_OK)
  {
    Error_Handler();
  }

}

static void MX_CAN2_Init(void)
{

  hcan2.Instance = CAN2;
  hcan2.Init.Prescaler = 3;
  hcan2.Init.Mode = CAN_MODE_NORMAL;
  hcan2.Init.SyncJumpWidth = CAN_SJW_1TQ;
  hcan2.Init.TimeSeg1 = CAN_BS1_10TQ;
  hcan2.Init.TimeSeg2 = CAN_BS2_3TQ;
  hcan2.Init.TimeTriggeredMode = DISABLE;
  hcan2.Init.AutoBusOff = DISABLE;
  hcan2.Init.AutoWakeUp = DISABLE;
  hcan2.Init.AutoRetransmission = DISABLE;
  hcan2.Init.ReceiveFifoLocked = DISABLE;
  hcan2.Init.TransmitFifoPriority = DISABLE;
  if (HAL_CAN_Init(&hcan2) != HAL_OK)
  {
    Error_Handler();
  }
  /* USER CODE BEGIN CAN2_Init 2 */

  CAN_FilterTypeDef can_filter_st;
  can_filter_st.FilterActivation = ENABLE;
  can_filter_st.FilterMode = CAN_FILTERMODE_IDMASK;
  can_filter_st.FilterScale = CAN_FILTERSCALE_32BIT;
  can_filter_st.FilterIdHigh = 0x0000;
  can_filter_st.FilterIdLow = 0x0000;
  can_filter_st.FilterMaskIdHigh = 0x0000;
  can_filter_st.FilterMaskIdLow = 0x0000;
  can_filter_st.FilterBank = 0;
  can_filter_st.FilterFIFOAssignment = CAN_RX_FIFO0;
  HAL_CAN_ConfigFilter(&hcan1, &can_filter_st);
  HAL_CAN_Start(&hcan1);
  HAL_CAN_ActivateNotification(&hcan1, CAN_IT_RX_FIFO0_MSG_PENDING);

  can_filter_st.SlaveStartFilterBank = 14;
  can_filter_st.FilterBank = 14;
  HAL_CAN_ConfigFilter(&hcan2, &can_filter_st);
  HAL_CAN_Start(&hcan2);
  HAL_CAN_ActivateNotification(&hcan2, CAN_IT_RX_FIFO0_MSG_PENDING);

  /* USER CODE END CAN2_Init 2 */

}

static void MX_CRC_Init(void)
{

  hcrc.Instance = CRC;
  if (HAL_CRC_Init(&hcrc) != HAL_OK)
  {
    Error_Handler();
  }

}

static void MX_I2C2_Init(void)
{

  hi2c2.Instance = I2C2;
  hi2c2.Init.ClockSpeed = 400000;
  hi2c2.Init.DutyCycle = I2C_DUTYCYCLE_2;
  hi2c2.Init.OwnAddress1 = 0;
  hi2c2.Init.AddressingMode = I2C_ADDRESSINGMODE_7BIT;
  hi2c2.Init.DualAddressMode = I2C_DUALADDRESS_DISABLE;
  hi2c2.Init.OwnAddress2 = 0;
  hi2c2.Init.GeneralCallMode = I2C_GENERALCALL_DISABLE;
  hi2c2.Init.NoStretchMode = I2C_NOSTRETCH_DISABLE;
  if (HAL_I2C_Init(&hi2c2) != HAL_OK)
  {
    Error_Handler();
  }
  /** Configure Analogue filter
  */
  if (HAL_I2CEx_ConfigAnalogFilter(&hi2c2, I2C_ANALOGFILTER_ENABLE) != HAL_OK)
  {
    Error_Handler();
  }
  /** Configure Digital filter
  */
  if (HAL_I2CEx_ConfigDigitalFilter(&hi2c2, 0) != HAL_OK)
  {
    Error_Handler();
  }

}

static void MX_RNG_Init(void)
{

  hrng.Instance = RNG;
  if (HAL_RNG_Init(&hrng) != HAL_OK)
  {
    Error_Handler();
  }

}

static void MX_RTC_Init(void)
{

  RTC_TimeTypeDef sTime = {0};
  RTC_DateTypeDef sDate = {0};

  /** Initialize RTC Only
  */
  hrtc.Instance = RTC;
  hrtc.Init.HourFormat = RTC_HOURFORMAT_24;
  hrtc.Init.AsynchPrediv = 124;
  hrtc.Init.SynchPrediv = 3199;
  hrtc.Init.OutPut = RTC_OUTPUT_DISABLE;
  hrtc.Init.OutPutPolarity = RTC_OUTPUT_POLARITY_HIGH;
  hrtc.Init.OutPutType = RTC_OUTPUT_TYPE_OPENDRAIN;
  if (HAL_RTC_Init(&hrtc) != HAL_OK)
  {
    Error_Handler();
  }

  /** Initialize RTC and set the Time and Date
  */
  sTime.Hours = 0x0;
  sTime.Minutes = 0x0;
  sTime.Seconds = 0x0;
  sTime.DayLightSaving = RTC_DAYLIGHTSAVING_NONE;
  sTime.StoreOperation = RTC_STOREOPERATION_RESET;
  if (HAL_RTC_SetTime(&hrtc, &sTime, RTC_FORMAT_BCD) != HAL_OK)
  {
    Error_Handler();
  }
  sDate.WeekDay = RTC_WEEKDAY_MONDAY;
  sDate.Month = RTC_MONTH_JANUARY;
  sDate.Date = 0x1;
  sDate.Year = 0x0;

  if (HAL_RTC_SetDate(&hrtc, &sDate, RTC_FORMAT_BCD) != HAL_OK)
  {
    Error_Handler();
  }

}

static void MX_SDIO_SD_Init(void)
{

  hsd.Instance = SDIO;
  hsd.Init.ClockEdge = SDIO_CLOCK_EDGE_RISING;
  hsd.Init.ClockBypass = SDIO_CLOCK_BYPASS_DISABLE;
  hsd.Init.ClockPowerSave = SDIO_CLOCK_POWER_SAVE_DISABLE;
  hsd.Init.BusWide = SDIO_BUS_WIDE_1B;
  hsd.Init.HardwareFlowControl = SDIO_HARDWARE_FLOW_CONTROL_DISABLE;
  hsd.Init.ClockDiv = 0;
  if (HAL_SD_Init(&hsd) != HAL_OK)
  {
    Error_Handler();
  }
  if (HAL_SD_ConfigWideBusOperation(&hsd, SDIO_BUS_WIDE_4B) != HAL_OK)
  {
    Error_Handler();
  }

}

static void MX_SPI1_Init(void)
{

  /* SPI1 parameter configuration*/
  hspi1.Instance = SPI1;
  hspi1.Init.Mode = SPI_MODE_MASTER;
  hspi1.Init.Direction = SPI_DIRECTION_1LINE;
  hspi1.Init.DataSize = SPI_DATASIZE_8BIT;
  hspi1.Init.CLKPolarity = SPI_POLARITY_LOW;
  hspi1.Init.CLKPhase = SPI_PHASE_1EDGE;
  hspi1.Init.NSS = SPI_NSS_SOFT;
  hspi1.Init.BaudRatePrescaler = SPI_BAUDRATEPRESCALER_2;
  hspi1.Init.FirstBit = SPI_FIRSTBIT_MSB;
  hspi1.Init.TIMode = SPI_TIMODE_DISABLE;
  hspi1.Init.CRCCalculation = SPI_CRCCALCULATION_DISABLE;
  hspi1.Init.CRCPolynomial = 10;
  if (HAL_SPI_Init(&hspi1) != HAL_OK)
  {
    Error_Handler();
  }

}

static void MX_SPI4_Init(void)
{

  /* SPI4 parameter configuration*/
  hspi4.Instance = SPI4;
  hspi4.Init.Mode = SPI_MODE_MASTER;
  hspi4.Init.Direction = SPI_DIRECTION_2LINES;
  hspi4.Init.DataSize = SPI_DATASIZE_8BIT;
  hspi4.Init.CLKPolarity = SPI_POLARITY_HIGH;
  hspi4.Init.CLKPhase = SPI_PHASE_2EDGE;
  hspi4.Init.NSS = SPI_NSS_SOFT;
  hspi4.Init.BaudRatePrescaler = SPI_BAUDRATEPRESCALER_256;
  hspi4.Init.FirstBit = SPI_FIRSTBIT_MSB;
  hspi4.Init.TIMode = SPI_TIMODE_DISABLE;
  hspi4.Init.CRCCalculation = SPI_CRCCALCULATION_DISABLE;
  hspi4.Init.CRCPolynomial = 10;
  if (HAL_SPI_Init(&hspi4) != HAL_OK)
  {
    Error_Handler();
  }

}

static void MX_SPI5_Init(void)
{

  /* SPI5 parameter configuration*/
  hspi5.Instance = SPI5;
  hspi5.Init.Mode = SPI_MODE_MASTER;
  hspi5.Init.Direction = SPI_DIRECTION_2LINES;
  hspi5.Init.DataSize = SPI_DATASIZE_8BIT;
  hspi5.Init.CLKPolarity = SPI_POLARITY_HIGH;
  hspi5.Init.CLKPhase = SPI_PHASE_2EDGE;
  hspi5.Init.NSS = SPI_NSS_SOFT;
  hspi5.Init.BaudRatePrescaler = SPI_BAUDRATEPRESCALER_256;
  hspi5.Init.FirstBit = SPI_FIRSTBIT_MSB;
  hspi5.Init.TIMode = SPI_TIMODE_DISABLE;
  hspi5.Init.CRCCalculation = SPI_CRCCALCULATION_DISABLE;
  hspi5.Init.CRCPolynomial = 10;
  if (HAL_SPI_Init(&hspi5) != HAL_OK)
  {
    Error_Handler();
  }

}

static void MX_TIM1_Init(void)
{

  TIM_ClockConfigTypeDef sClockSourceConfig = {0};
  TIM_MasterConfigTypeDef sMasterConfig = {0};
  TIM_OC_InitTypeDef sConfigOC = {0};
  TIM_BreakDeadTimeConfigTypeDef sBreakDeadTimeConfig = {0};

  htim1.Instance = TIM1;
  htim1.Init.Prescaler = 41;
  htim1.Init.CounterMode = TIM_COUNTERMODE_UP;
  htim1.Init.Period = 1999;
  htim1.Init.ClockDivision = TIM_CLOCKDIVISION_DIV4;
  htim1.Init.RepetitionCounter = 0;
  htim1.Init.AutoReloadPreload = TIM_AUTORELOAD_PRELOAD_DISABLE;
  if (HAL_TIM_Base_Init(&htim1) != HAL_OK)
  {
    Error_Handler();
  }
  sClockSourceConfig.ClockSource = TIM_CLOCKSOURCE_INTERNAL;
  if (HAL_TIM_ConfigClockSource(&htim1, &sClockSourceConfig) != HAL_OK)
  {
    Error_Handler();
  }
  if (HAL_TIM_PWM_Init(&htim1) != HAL_OK)
  {
    Error_Handler();
  }
  sMasterConfig.MasterOutputTrigger = TIM_TRGO_RESET;
  sMasterConfig.MasterSlaveMode = TIM_MASTERSLAVEMODE_DISABLE;
  if (HAL_TIMEx_MasterConfigSynchronization(&htim1, &sMasterConfig) != HAL_OK)
  {
    Error_Handler();
  }
  sConfigOC.OCMode = TIM_OCMODE_PWM1;
  sConfigOC.Pulse = 1000;
  sConfigOC.OCPolarity = TIM_OCPOLARITY_HIGH;
  sConfigOC.OCNPolarity = TIM_OCNPOLARITY_HIGH;
  sConfigOC.OCFastMode = TIM_OCFAST_DISABLE;
  sConfigOC.OCIdleState = TIM_OCIDLESTATE_RESET;
  sConfigOC.OCNIdleState = TIM_OCNIDLESTATE_RESET;
  if (HAL_TIM_PWM_ConfigChannel(&htim1, &sConfigOC, TIM_CHANNEL_1) != HAL_OK)
  {
    Error_Handler();
  }
  if (HAL_TIM_PWM_ConfigChannel(&htim1, &sConfigOC, TIM_CHANNEL_2) != HAL_OK)
  {
    Error_Handler();
  }
  if (HAL_TIM_PWM_ConfigChannel(&htim1, &sConfigOC, TIM_CHANNEL_3) != HAL_OK)
  {
    Error_Handler();
  }
  if (HAL_TIM_PWM_ConfigChannel(&htim1, &sConfigOC, TIM_CHANNEL_4) != HAL_OK)
  {
    Error_Handler();
  }
  sBreakDeadTimeConfig.OffStateRunMode = TIM_OSSR_DISABLE;
  sBreakDeadTimeConfig.OffStateIDLEMode = TIM_OSSI_DISABLE;
  sBreakDeadTimeConfig.LockLevel = TIM_LOCKLEVEL_OFF;
  sBreakDeadTimeConfig.DeadTime = 0;
  sBreakDeadTimeConfig.BreakState = TIM_BREAK_DISABLE;
  sBreakDeadTimeConfig.BreakPolarity = TIM_BREAKPOLARITY_HIGH;
  sBreakDeadTimeConfig.AutomaticOutput = TIM_AUTOMATICOUTPUT_DISABLE;
  if (HAL_TIMEx_ConfigBreakDeadTime(&htim1, &sBreakDeadTimeConfig) != HAL_OK)
  {
    Error_Handler();
  }
  HAL_TIM_MspPostInit(&htim1);

}

static void MX_TIM2_Init(void)
{

  TIM_ClockConfigTypeDef sClockSourceConfig = {0};
  TIM_MasterConfigTypeDef sMasterConfig = {0};
  TIM_OC_InitTypeDef sConfigOC = {0};

  htim2.Instance = TIM2;
  htim2.Init.Prescaler = 83;
  htim2.Init.CounterMode = TIM_COUNTERMODE_UP;
  htim2.Init.Period = 19999;
  htim2.Init.ClockDivision = TIM_CLOCKDIVISION_DIV1;
  htim2.Init.AutoReloadPreload = TIM_AUTORELOAD_PRELOAD_DISABLE;
  if (HAL_TIM_Base_Init(&htim2) != HAL_OK)
  {
    Error_Handler();
  }
  sClockSourceConfig.ClockSource = TIM_CLOCKSOURCE_INTERNAL;
  if (HAL_TIM_ConfigClockSource(&htim2, &sClockSourceConfig) != HAL_OK)
  {
    Error_Handler();
  }
  if (HAL_TIM_PWM_Init(&htim2) != HAL_OK)
  {
    Error_Handler();
  }
  sMasterConfig.MasterOutputTrigger = TIM_TRGO_RESET;
  sMasterConfig.MasterSlaveMode = TIM_MASTERSLAVEMODE_DISABLE;
  if (HAL_TIMEx_MasterConfigSynchronization(&htim2, &sMasterConfig) != HAL_OK)
  {
    Error_Handler();
  }
  sConfigOC.OCMode = TIM_OCMODE_PWM1;
  sConfigOC.Pulse = 0;
  sConfigOC.OCPolarity = TIM_OCPOLARITY_HIGH;
  sConfigOC.OCFastMode = TIM_OCFAST_DISABLE;
  if (HAL_TIM_PWM_ConfigChannel(&htim2, &sConfigOC, TIM_CHANNEL_1) != HAL_OK)
  {
    Error_Handler();
  }
  if (HAL_TIM_PWM_ConfigChannel(&htim2, &sConfigOC, TIM_CHANNEL_2) != HAL_OK)
  {
    Error_Handler();
  }
  if (HAL_TIM_PWM_ConfigChannel(&htim2, &sConfigOC, TIM_CHANNEL_3) != HAL_OK)
  {
    Error_Handler();
  }
  if (HAL_TIM_PWM_ConfigChannel(&htim2, &sConfigOC, TIM_CHANNEL_4) != HAL_OK)
  {
    Error_Handler();
  }
  HAL_TIM_MspPostInit(&htim2);

}

static void MX_TIM3_Init(void)
{

  TIM_ClockConfigTypeDef sClockSourceConfig = {0};
  TIM_MasterConfigTypeDef sMasterConfig = {0};
  TIM_OC_InitTypeDef sConfigOC = {0};

  htim3.Instance = TIM3;
  htim3.Init.Prescaler = 0;
  htim3.Init.CounterMode = TIM_COUNTERMODE_UP;
  htim3.Init.Period = 5000;
  htim3.Init.ClockDivision = TIM_CLOCKDIVISION_DIV1;
  htim3.Init.AutoReloadPreload = TIM_AUTORELOAD_PRELOAD_DISABLE;
  if (HAL_TIM_Base_Init(&htim3) != HAL_OK)
  {
    Error_Handler();
  }
  sClockSourceConfig.ClockSource = TIM_CLOCKSOURCE_INTERNAL;
  if (HAL_TIM_ConfigClockSource(&htim3, &sClockSourceConfig) != HAL_OK)
  {
    Error_Handler();
  }
  if (HAL_TIM_PWM_Init(&htim3) != HAL_OK)
  {
    Error_Handler();
  }
  sMasterConfig.MasterOutputTrigger = TIM_TRGO_RESET;
  sMasterConfig.MasterSlaveMode = TIM_MASTERSLAVEMODE_DISABLE;
  if (HAL_TIMEx_MasterConfigSynchronization(&htim3, &sMasterConfig) != HAL_OK)
  {
    Error_Handler();
  }
  sConfigOC.OCMode = TIM_OCMODE_PWM1;
  sConfigOC.Pulse = 0;
  sConfigOC.OCPolarity = TIM_OCPOLARITY_HIGH;
  sConfigOC.OCFastMode = TIM_OCFAST_DISABLE;
  if (HAL_TIM_PWM_ConfigChannel(&htim3, &sConfigOC, TIM_CHANNEL_2) != HAL_OK)
  {
    Error_Handler();
  }
  /* USER CODE BEGIN TIM3_Init 2 */

    HAL_TIM_Base_Start(&htim3);
    HAL_TIM_PWM_Start(&htim3, TIM_CHANNEL_2);

  /* USER CODE END TIM3_Init 2 */
  HAL_TIM_MspPostInit(&htim3);

}

static void MX_TIM4_Init(void)
{

  TIM_ClockConfigTypeDef sClockSourceConfig = {0};
  TIM_MasterConfigTypeDef sMasterConfig = {0};
  TIM_OC_InitTypeDef sConfigOC = {0};

  htim4.Instance = TIM4;
  htim4.Init.Prescaler = 83;
  htim4.Init.CounterMode = TIM_COUNTERMODE_UP;
  htim4.Init.Period = 19999;
  htim4.Init.ClockDivision = TIM_CLOCKDIVISION_DIV1;
  htim4.Init.AutoReloadPreload = TIM_AUTORELOAD_PRELOAD_DISABLE;
  if (HAL_TIM_Base_Init(&htim4) != HAL_OK)
  {
    Error_Handler();
  }
  sClockSourceConfig.ClockSource = TIM_CLOCKSOURCE_INTERNAL;
  if (HAL_TIM_ConfigClockSource(&htim4, &sClockSourceConfig) != HAL_OK)
  {
    Error_Handler();
  }
  if (HAL_TIM_PWM_Init(&htim4) != HAL_OK)
  {
    Error_Handler();
  }
  sMasterConfig.MasterOutputTrigger = TIM_TRGO_RESET;
  sMasterConfig.MasterSlaveMode = TIM_MASTERSLAVEMODE_DISABLE;
  if (HAL_TIMEx_MasterConfigSynchronization(&htim4, &sMasterConfig) != HAL_OK)
  {
    Error_Handler();
  }
  sConfigOC.OCMode = TIM_OCMODE_PWM1;
  sConfigOC.Pulse = 0;
  sConfigOC.OCPolarity = TIM_OCPOLARITY_HIGH;
  sConfigOC.OCFastMode = TIM_OCFAST_DISABLE;
  if (HAL_TIM_PWM_ConfigChannel(&htim4, &sConfigOC, TIM_CHANNEL_1) != HAL_OK)
  {
    Error_Handler();
  }
  if (HAL_TIM_PWM_ConfigChannel(&htim4, &sConfigOC, TIM_CHANNEL_2) != HAL_OK)
  {
    Error_Handler();
  }
  if (HAL_TIM_PWM_ConfigChannel(&htim4, &sConfigOC, TIM_CHANNEL_3) != HAL_OK)
  {
    Error_Handler();
  }
  if (HAL_TIM_PWM_ConfigChannel(&htim4, &sConfigOC, TIM_CHANNEL_4) != HAL_OK)
  {
    Error_Handler();
  }
  HAL_TIM_MspPostInit(&htim4);

}

static void MX_TIM5_Init(void)
{

  TIM_ClockConfigTypeDef sClockSourceConfig = {0};
  TIM_MasterConfigTypeDef sMasterConfig = {0};
  TIM_OC_InitTypeDef sConfigOC = {0};

  htim5.Instance = TIM5;
  htim5.Init.Prescaler = 83;
  htim5.Init.CounterMode = TIM_COUNTERMODE_UP;
  htim5.Init.Period = 19999;
  htim5.Init.ClockDivision = TIM_CLOCKDIVISION_DIV1;
  htim5.Init.AutoReloadPreload = TIM_AUTORELOAD_PRELOAD_DISABLE;
  if (HAL_TIM_Base_Init(&htim5) != HAL_OK)
  {
    Error_Handler();
  }
  sClockSourceConfig.ClockSource = TIM_CLOCKSOURCE_INTERNAL;
  if (HAL_TIM_ConfigClockSource(&htim5, &sClockSourceConfig) != HAL_OK)
  {
    Error_Handler();
  }
  if (HAL_TIM_PWM_Init(&htim5) != HAL_OK)
  {
    Error_Handler();
  }
  sMasterConfig.MasterOutputTrigger = TIM_TRGO_RESET;
  sMasterConfig.MasterSlaveMode = TIM_MASTERSLAVEMODE_DISABLE;
  if (HAL_TIMEx_MasterConfigSynchronization(&htim5, &sMasterConfig) != HAL_OK)
  {
    Error_Handler();
  }
  sConfigOC.OCMode = TIM_OCMODE_PWM1;
  sConfigOC.Pulse = 0;
  sConfigOC.OCPolarity = TIM_OCPOLARITY_HIGH;
  sConfigOC.OCFastMode = TIM_OCFAST_DISABLE;
  if (HAL_TIM_PWM_ConfigChannel(&htim5, &sConfigOC, TIM_CHANNEL_1) != HAL_OK)
  {
    Error_Handler();
  }
  if (HAL_TIM_PWM_ConfigChannel(&htim5, &sConfigOC, TIM_CHANNEL_2) != HAL_OK)
  {
    Error_Handler();
  }
  if (HAL_TIM_PWM_ConfigChannel(&htim5, &sConfigOC, TIM_CHANNEL_3) != HAL_OK)
  {
    Error_Handler();
  }
  if (HAL_TIM_PWM_ConfigChannel(&htim5, &sConfigOC, TIM_CHANNEL_4) != HAL_OK)
  {
    Error_Handler();
  }
  HAL_TIM_MspPostInit(&htim5);

}

static void MX_TIM8_Init(void)
{

  TIM_ClockConfigTypeDef sClockSourceConfig = {0};
  TIM_MasterConfigTypeDef sMasterConfig = {0};
  TIM_OC_InitTypeDef sConfigOC = {0};
  TIM_BreakDeadTimeConfigTypeDef sBreakDeadTimeConfig = {0};

  htim8.Instance = TIM8;
  htim8.Init.Prescaler = 167;
  htim8.Init.CounterMode = TIM_COUNTERMODE_UP;
  htim8.Init.Period = 19999;
  htim8.Init.ClockDivision = TIM_CLOCKDIVISION_DIV1;
  htim8.Init.RepetitionCounter = 0;
  htim8.Init.AutoReloadPreload = TIM_AUTORELOAD_PRELOAD_DISABLE;
  if (HAL_TIM_Base_Init(&htim8) != HAL_OK)
  {
    Error_Handler();
  }
  sClockSourceConfig.ClockSource = TIM_CLOCKSOURCE_INTERNAL;
  if (HAL_TIM_ConfigClockSource(&htim8, &sClockSourceConfig) != HAL_OK)
  {
    Error_Handler();
  }
  if (HAL_TIM_PWM_Init(&htim8) != HAL_OK)
  {
    Error_Handler();
  }
  sMasterConfig.MasterOutputTrigger = TIM_TRGO_RESET;
  sMasterConfig.MasterSlaveMode = TIM_MASTERSLAVEMODE_DISABLE;
  if (HAL_TIMEx_MasterConfigSynchronization(&htim8, &sMasterConfig) != HAL_OK)
  {
    Error_Handler();
  }
  sConfigOC.OCMode = TIM_OCMODE_PWM1;
  sConfigOC.Pulse = 0;
  sConfigOC.OCPolarity = TIM_OCPOLARITY_HIGH;
  sConfigOC.OCNPolarity = TIM_OCNPOLARITY_HIGH;
  sConfigOC.OCFastMode = TIM_OCFAST_DISABLE;
  sConfigOC.OCIdleState = TIM_OCIDLESTATE_RESET;
  sConfigOC.OCNIdleState = TIM_OCNIDLESTATE_RESET;
  if (HAL_TIM_PWM_ConfigChannel(&htim8, &sConfigOC, TIM_CHANNEL_1) != HAL_OK)
  {
    Error_Handler();
  }
  if (HAL_TIM_PWM_ConfigChannel(&htim8, &sConfigOC, TIM_CHANNEL_2) != HAL_OK)
  {
    Error_Handler();
  }
  if (HAL_TIM_PWM_ConfigChannel(&htim8, &sConfigOC, TIM_CHANNEL_3) != HAL_OK)
  {
    Error_Handler();
  }
  if (HAL_TIM_PWM_ConfigChannel(&htim8, &sConfigOC, TIM_CHANNEL_4) != HAL_OK)
  {
    Error_Handler();
  }
  sBreakDeadTimeConfig.OffStateRunMode = TIM_OSSR_DISABLE;
  sBreakDeadTimeConfig.OffStateIDLEMode = TIM_OSSI_DISABLE;
  sBreakDeadTimeConfig.LockLevel = TIM_LOCKLEVEL_OFF;
  sBreakDeadTimeConfig.DeadTime = 0;
  sBreakDeadTimeConfig.BreakState = TIM_BREAK_DISABLE;
  sBreakDeadTimeConfig.BreakPolarity = TIM_BREAKPOLARITY_HIGH;
  sBreakDeadTimeConfig.AutomaticOutput = TIM_AUTOMATICOUTPUT_DISABLE;
  if (HAL_TIMEx_ConfigBreakDeadTime(&htim8, &sBreakDeadTimeConfig) != HAL_OK)
  {
    Error_Handler();
  }
  HAL_TIM_MspPostInit(&htim8);

}

static void MX_TIM12_Init(void)
{

  TIM_ClockConfigTypeDef sClockSourceConfig = {0};
  TIM_OC_InitTypeDef sConfigOC = {0};

  htim12.Instance = TIM12;
  htim12.Init.Prescaler = 90;
  htim12.Init.CounterMode = TIM_COUNTERMODE_UP;
  htim12.Init.Period = 30000;
  htim12.Init.ClockDivision = TIM_CLOCKDIVISION_DIV4;
  htim12.Init.AutoReloadPreload = TIM_AUTORELOAD_PRELOAD_DISABLE;
  if (HAL_TIM_Base_Init(&htim12) != HAL_OK)
  {
    Error_Handler();
  }
  sClockSourceConfig.ClockSource = TIM_CLOCKSOURCE_INTERNAL;
  if (HAL_TIM_ConfigClockSource(&htim12, &sClockSourceConfig) != HAL_OK)
  {
    Error_Handler();
  }
  if (HAL_TIM_PWM_Init(&htim12) != HAL_OK)
  {
    Error_Handler();
  }
  sConfigOC.OCMode = TIM_OCMODE_PWM1;
  sConfigOC.Pulse = 0;
  sConfigOC.OCPolarity = TIM_OCPOLARITY_HIGH;
  sConfigOC.OCFastMode = TIM_OCFAST_DISABLE;
  if (HAL_TIM_PWM_ConfigChannel(&htim12, &sConfigOC, TIM_CHANNEL_1) != HAL_OK)
  {
    Error_Handler();
  }
  /* USER CODE BEGIN TIM12_Init 2 */

    HAL_TIM_Base_Start(&htim12);
    HAL_TIM_PWM_Start(&htim12, TIM_CHANNEL_1);
  /* USER CODE END TIM12_Init 2 */
  HAL_TIM_MspPostInit(&htim12);

}

static void MX_UART7_Init(void)
{

  huart7.Instance = UART7;
  huart7.Init.BaudRate = 115200;
  huart7.Init.WordLength = UART_WORDLENGTH_8B;
  huart7.Init.StopBits = UART_STOPBITS_1;
  huart7.Init.Parity = UART_PARITY_NONE;
  huart7.Init.Mode = UART_MODE_TX_RX;
  huart7.Init.HwFlowCtl = UART_HWCONTROL_NONE;
  huart7.Init.OverSampling = UART_OVERSAMPLING_16;
  if (HAL_UART_Init(&huart7) != HAL_OK)
  {
    Error_Handler();
  }

}

static void MX_UART8_Init(void)
{

  huart8.Instance = UART8;
  huart8.Init.BaudRate = 115200;
  huart8.Init.WordLength = UART_WORDLENGTH_8B;
  huart8.Init.StopBits = UART_STOPBITS_1;
  huart8.Init.Parity = UART_PARITY_NONE;
  huart8.Init.Mode = UART_MODE_TX_RX;
  huart8.Init.HwFlowCtl = UART_HWCONTROL_NONE;
  huart8.Init.OverSampling = UART_OVERSAMPLING_16;
  if (HAL_UART_Init(&huart8) != HAL_OK)
  {
    Error_Handler();
  }

}

static void MX_USART1_UART_Init(void)
{

  huart1.Instance = USART1;
  huart1.Init.BaudRate = 100000;
  huart1.Init.WordLength = UART_WORDLENGTH_8B;
  huart1.Init.StopBits = UART_STOPBITS_1;
  huart1.Init.Parity = UART_PARITY_EVEN;
  huart1.Init.Mode = UART_MODE_RX;
  huart1.Init.HwFlowCtl = UART_HWCONTROL_NONE;
  huart1.Init.OverSampling = UART_OVERSAMPLING_16;
  if (HAL_UART_Init(&huart1) != HAL_OK)
  {
    Error_Handler();
  }

}

static void MX_USART2_UART_Init(void)
{

  huart2.Instance = USART2;
  huart2.Init.BaudRate = 115200;
  huart2.Init.WordLength = UART_WORDLENGTH_8B;
  huart2.Init.StopBits = UART_STOPBITS_1;
  huart2.Init.Parity = UART_PARITY_NONE;
  huart2.Init.Mode = UART_MODE_TX_RX;
  huart2.Init.HwFlowCtl = UART_HWCONTROL_NONE;
  huart2.Init.OverSampling = UART_OVERSAMPLING_16;
  if (HAL_UART_Init(&huart2) != HAL_OK)
  {
    Error_Handler();
  }

}

static void MX_USART3_UART_Init(void)
{

  huart3.Instance = USART3;
  huart3.Init.BaudRate = 115200;
  huart3.Init.WordLength = UART_WORDLENGTH_8B;
  huart3.Init.StopBits = UART_STOPBITS_1;
  huart3.Init.Parity = UART_PARITY_NONE;
  huart3.Init.Mode = UART_MODE_TX_RX;
  huart3.Init.HwFlowCtl = UART_HWCONTROL_NONE;
  huart3.Init.OverSampling = UART_OVERSAMPLING_16;
  if (HAL_UART_Init(&huart3) != HAL_OK)
  {
    Error_Handler();
  }

}

static void MX_USART6_UART_Init(void)
{

  huart6.Instance = USART6;
  huart6.Init.BaudRate = 115200;
  huart6.Init.WordLength = UART_WORDLENGTH_8B;
  huart6.Init.StopBits = UART_STOPBITS_1;
  huart6.Init.Parity = UART_PARITY_NONE;
  huart6.Init.Mode = UART_MODE_TX_RX;
  huart6.Init.HwFlowCtl = UART_HWCONTROL_NONE;
  huart6.Init.OverSampling = UART_OVERSAMPLING_16;
  if (HAL_UART_Init(&huart6) != HAL_OK)
  {
    Error_Handler();
  }

}

static void MX_DMA_Init(void)
{
  /* DMA controller clock enable */
  __HAL_RCC_DMA2_CLK_ENABLE();
  __HAL_RCC_DMA1_CLK_ENABLE();

  /* DMA interrupt init */
  /* DMA1_Stream5_IRQn interrupt configuration */
  HAL_NVIC_SetPriority(DMA1_Stream5_IRQn, 5, 0);
  HAL_NVIC_EnableIRQ(DMA1_Stream5_IRQn);
  /* DMA1_Stream6_IRQn interrupt configuration */
  HAL_NVIC_SetPriority(DMA1_Stream6_IRQn, 5, 0);
  HAL_NVIC_EnableIRQ(DMA1_Stream6_IRQn);
  /* DMA2_Stream1_IRQn interrupt configuration */
  HAL_NVIC_SetPriority(DMA2_Stream1_IRQn, 5, 0);
  HAL_NVIC_EnableIRQ(DMA2_Stream1_IRQn);
  /* DMA2_Stream2_IRQn interrupt configuration */
  HAL_NVIC_SetPriority(DMA2_Stream2_IRQn, 5, 0);
  HAL_NVIC_EnableIRQ(DMA2_Stream2_IRQn);
  /* DMA2_Stream4_IRQn interrupt configuration */
  HAL_NVIC_SetPriority(DMA2_Stream4_IRQn, 5, 0);
  HAL_NVIC_EnableIRQ(DMA2_Stream4_IRQn);
  /* DMA2_Stream5_IRQn interrupt configuration */
  HAL_NVIC_SetPriority(DMA2_Stream5_IRQn, 5, 0);
  HAL_NVIC_EnableIRQ(DMA2_Stream5_IRQn);
  /* DMA2_Stream6_IRQn interrupt configuration */
  HAL_NVIC_SetPriority(DMA2_Stream6_IRQn, 5, 0);
  HAL_NVIC_EnableIRQ(DMA2_Stream6_IRQn);

}

static void MX_GPIO_Init(void)
{
  GPIO_InitTypeDef GPIO_InitStruct = {0};

  /* GPIO Ports Clock Enable */
  __HAL_RCC_GPIOE_CLK_ENABLE();
  __HAL_RCC_GPIOB_CLK_ENABLE();
  __HAL_RCC_GPIOG_CLK_ENABLE();
  __HAL_RCC_GPIOC_CLK_ENABLE();
  __HAL_RCC_GPIOA_CLK_ENABLE();
  __HAL_RCC_GPIOD_CLK_ENABLE();
  __HAL_RCC_GPIOI_CLK_ENABLE();
  __HAL_RCC_GPIOF_CLK_ENABLE();
  __HAL_RCC_GPIOH_CLK_ENABLE();

  /*Configure GPIO pin Output Level */
  HAL_GPIO_WritePin(GPIOE, IST8310_RST_Pin|SPI4_NSS_Pin|LED_RED_Pin, GPIO_PIN_SET);

  /*Configure GPIO pin Output Level */
  HAL_GPIO_WritePin(GPIOG, LASER_Pin|FLOW_LED_8_Pin|FLOW_LED_7_Pin|FLOW_LED_6_Pin
                          |FLOW_LED_5_Pin|FLOW_LED_4_Pin|FLOW_LED_3_Pin|FLOW_LED_2_Pin
                          |FLOW_LED_1_Pin, GPIO_PIN_SET);

  /*Configure GPIO pin Output Level */
  HAL_GPIO_WritePin(GPIOB, OLED_DC_Pin|OLED_RST_Pin, GPIO_PIN_SET);

  /*Configure GPIO pin Output Level */
  HAL_GPIO_WritePin(GPIOH, POWER1_CTRL_Pin|POWER2_CTRL_Pin|POWER3_CTRL_Pin|POWER4_CTRL_Pin, GPIO_PIN_RESET);

  /*Configure GPIO pin Output Level */
  HAL_GPIO_WritePin(GPIOF, SPI5_NSS_Pin|LED_GREEN_Pin, GPIO_PIN_SET);

  /*Configure GPIO pin : IST8310_INT_Pin */
  GPIO_InitStruct.Pin = IST8310_INT_Pin;
  GPIO_InitStruct.Mode = GPIO_MODE_IT_FALLING;
  GPIO_InitStruct.Pull = GPIO_PULLUP;
  HAL_GPIO_Init(IST8310_INT_GPIO_Port, &GPIO_InitStruct);

  /*Configure GPIO pin : IST8310_RST_Pin */
  GPIO_InitStruct.Pin = IST8310_RST_Pin;
  GPIO_InitStruct.Mode = GPIO_MODE_OUTPUT_PP;
  GPIO_InitStruct.Pull = GPIO_PULLUP;
  GPIO_InitStruct.Speed = GPIO_SPEED_FREQ_LOW;
  HAL_GPIO_Init(IST8310_RST_GPIO_Port, &GPIO_InitStruct);

  /*Configure GPIO pin : IMU_INT_Pin */
  GPIO_InitStruct.Pin = IMU_INT_Pin;
  GPIO_InitStruct.Mode = GPIO_MODE_IT_FALLING;
  GPIO_InitStruct.Pull = GPIO_PULLUP;
  HAL_GPIO_Init(IMU_INT_GPIO_Port, &GPIO_InitStruct);

  /*Configure GPIO pins : LASER_Pin FLOW_LED_8_Pin FLOW_LED_7_Pin FLOW_LED_6_Pin
                           FLOW_LED_5_Pin FLOW_LED_4_Pin FLOW_LED_3_Pin FLOW_LED_2_Pin
                           FLOW_LED_1_Pin */
  GPIO_InitStruct.Pin = LASER_Pin|FLOW_LED_8_Pin|FLOW_LED_7_Pin|FLOW_LED_6_Pin
                          |FLOW_LED_5_Pin|FLOW_LED_4_Pin|FLOW_LED_3_Pin|FLOW_LED_2_Pin
                          |FLOW_LED_1_Pin;
  GPIO_InitStruct.Mode = GPIO_MODE_OUTPUT_PP;
  GPIO_InitStruct.Pull = GPIO_PULLUP;
  GPIO_InitStruct.Speed = GPIO_SPEED_FREQ_MEDIUM;
  HAL_GPIO_Init(GPIOG, &GPIO_InitStruct);

  /*Configure GPIO pin : SPI4_NSS_Pin */
  GPIO_InitStruct.Pin = SPI4_NSS_Pin;
  GPIO_InitStruct.Mode = GPIO_MODE_OUTPUT_PP;
  GPIO_InitStruct.Pull = GPIO_PULLUP;
  GPIO_InitStruct.Speed = GPIO_SPEED_FREQ_VERY_HIGH;
  HAL_GPIO_Init(SPI4_NSS_GPIO_Port, &GPIO_InitStruct);

  /*Configure GPIO pin : OLED_DC_Pin */
  GPIO_InitStruct.Pin = OLED_DC_Pin;
  GPIO_InitStruct.Mode = GPIO_MODE_OUTPUT_PP;
  GPIO_InitStruct.Pull = GPIO_PULLUP;
  GPIO_InitStruct.Speed = GPIO_SPEED_FREQ_VERY_HIGH;
  HAL_GPIO_Init(OLED_DC_GPIO_Port, &GPIO_InitStruct);

  /*Configure GPIO pins : POWER1_CTRL_Pin POWER2_CTRL_Pin POWER3_CTRL_Pin POWER4_CTRL_Pin */
  GPIO_InitStruct.Pin = POWER1_CTRL_Pin|POWER2_CTRL_Pin|POWER3_CTRL_Pin|POWER4_CTRL_Pin;
  GPIO_InitStruct.Mode = GPIO_MODE_OUTPUT_PP;
  GPIO_InitStruct.Pull = GPIO_PULLDOWN;
  GPIO_InitStruct.Speed = GPIO_SPEED_FREQ_MEDIUM;
  HAL_GPIO_Init(GPIOH, &GPIO_InitStruct);

  /*Configure GPIO pin : SPI5_NSS_Pin */
  GPIO_InitStruct.Pin = SPI5_NSS_Pin;
  GPIO_InitStruct.Mode = GPIO_MODE_OUTPUT_PP;
  GPIO_InitStruct.Pull = GPIO_PULLUP;
  GPIO_InitStruct.Speed = GPIO_SPEED_FREQ_VERY_HIGH;
  HAL_GPIO_Init(SPI5_NSS_GPIO_Port, &GPIO_InitStruct);

  /*Configure GPIO pin : SHOOT_INPUT_Pin */
  GPIO_InitStruct.Pin = SHOOT_INPUT_Pin;
  GPIO_InitStruct.Mode = GPIO_MODE_INPUT;
  GPIO_InitStruct.Pull = GPIO_PULLUP;
  HAL_GPIO_Init(SHOOT_INPUT_GPIO_Port, &GPIO_InitStruct);

  /*Configure GPIO pin : KEY_Pin */
  GPIO_InitStruct.Pin = KEY_Pin;
  GPIO_InitStruct.Mode = GPIO_MODE_INPUT;
  GPIO_InitStruct.Pull = GPIO_NOPULL;
  HAL_GPIO_Init(KEY_GPIO_Port, &GPIO_InitStruct);

  /*Configure GPIO pin : LED_RED_Pin */
  GPIO_InitStruct.Pin = LED_RED_Pin;
  GPIO_InitStruct.Mode = GPIO_MODE_OUTPUT_PP;
  GPIO_InitStruct.Pull = GPIO_PULLUP;
  GPIO_InitStruct.Speed = GPIO_SPEED_FREQ_MEDIUM;
  HAL_GPIO_Init(LED_RED_GPIO_Port, &GPIO_InitStruct);

  /*Configure GPIO pin : LED_GREEN_Pin */
  GPIO_InitStruct.Pin = LED_GREEN_Pin;
  GPIO_InitStruct.Mode = GPIO_MODE_OUTPUT_PP;
  GPIO_InitStruct.Pull = GPIO_PULLUP;
  GPIO_InitStruct.Speed = GPIO_SPEED_FREQ_MEDIUM;
  HAL_GPIO_Init(LED_GREEN_GPIO_Port, &GPIO_InitStruct);

  /*Configure GPIO pin : SD_EXTI_Pin */
  GPIO_InitStruct.Pin = SD_EXTI_Pin;
  GPIO_InitStruct.Mode = GPIO_MODE_INPUT;
  GPIO_InitStruct.Pull = GPIO_PULLUP;
  HAL_GPIO_Init(SD_EXTI_GPIO_Port, &GPIO_InitStruct);

  /*Configure GPIO pin : OLED_RST_Pin */
  GPIO_InitStruct.Pin = OLED_RST_Pin;
  GPIO_InitStruct.Mode = GPIO_MODE_OUTPUT_PP;
  GPIO_InitStruct.Pull = GPIO_PULLUP;
  GPIO_InitStruct.Speed = GPIO_SPEED_FREQ_LOW;
  HAL_GPIO_Init(OLED_RST_GPIO_Port, &GPIO_InitStruct);

  /* EXTI interrupt init*/
  HAL_NVIC_SetPriority(EXTI3_IRQn, 5, 0);
  HAL_NVIC_EnableIRQ(EXTI3_IRQn);

  HAL_NVIC_SetPriority(EXTI9_5_IRQn, 5, 0);
  HAL_NVIC_EnableIRQ(EXTI9_5_IRQn);

	//config GPIO use
	GPIO_InitStruct.Pin = GPIO_PIN_6|GPIO_PIN_5;
  GPIO_InitStruct.Mode = GPIO_MODE_OUTPUT_OD;
  GPIO_InitStruct.Pull = GPIO_PULLUP;
  GPIO_InitStruct.Speed = GPIO_SPEED_FREQ_LOW;
  HAL_GPIO_Init(GPIOE, &GPIO_InitStruct);

}

__weak void led_trigger_task(void const * argument)
{
  /* init code for USB_DEVICE */
  MX_USB_DEVICE_Init();

  for(;;)
  {
    osDelay(1);
  }
}

void Error_Handler(void)
{
}

/************************ (C) COPYRIGHT STMicroelectronics *****END OF FILE****/
